# S32K142W_M4 register map
Vendor: NXP Semiconductors; File version: 1.0
CPU: CM4 r0p1, little endian, MPU, FPU, VTOR, 4 interrupt priority bits
Registers are 32-bit, read-write, reset 0x0 unless marked. A register's access mark holds for its fields unless they carry their own. Offsets are from the block's base; [hi:lo] are bit positions; {n}, {i} and the like mark numbered series; 'fields as' and 'values as' point back to an identical list.

## MCM — Core Platform Miscellaneous Control Module
Base 0xE0080000; register names take the prefix MCM_
0x08 PLASC 16-bit ro reset 0x7 — Crossbar Switch (AXBS) Slave Configuration
  [7:0] ASC — Each bit in the ASC field indicates whether there is a corresponding connection to the crossbar switch's slave input port.
    0=A bus slave connection to AXBS input port n is absent; 1=A bus slave connection to AXBS input port n is present
0x0A PLAMC 16-bit ro reset 0x7 — Crossbar Switch (AXBS) Master Configuration
  [7:0] AMC — Each bit in the AMC field indicates whether there is a corresponding connection to the AXBS master input port.
    0=A bus master connection to AXBS input port n is absent; 1=A bus master connection to AXBS input port n is present
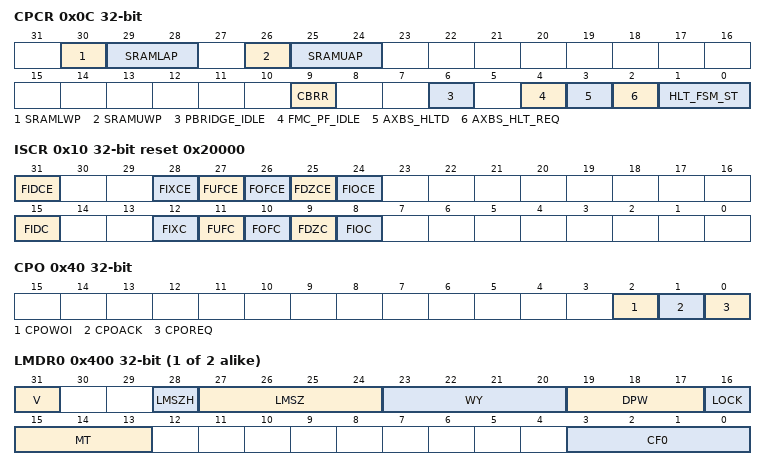
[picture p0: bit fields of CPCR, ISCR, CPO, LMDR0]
0x0C CPCR (reset mask 0xFFFFFFAF) — Core Platform Control Register
  [30] SRAMLWP — SRAM_L Write Protect
  [29:28] SRAMLAP — SRAM_L Arbitration Priority
    0=Round robin; 1=Special round robin (favors SRAM backdoor accesses over the processor); 2=Fixed priority. Processor has highest, backdoor has lowest; 3=Fixed priority. Backdoor has highest, processor has lowest
  [26] SRAMUWP — SRAM_U Write Protect
  [25:24] SRAMUAP — SRAM_U Arbitration Priority
    values as SRAMLAP
  [9] CBRR — Crossbar Round-robin Arbitration Enable
    0=Fixed-priority arbitration; 1=Round-robin arbitration
  [6] PBRIDGE_IDLE ro — Peripheral Bridge Idle
    0=PBRIDGE is not idle; 1=PBRIDGE is currently idle
  [4] FMC_PF_IDLE ro — Flash Memory Controller Program Flash Idle
    0=FMC program flash is not idle; 1=FMC program flash is currently idle
  [3] AXBS_HLTD ro — AXBS Halted
    0=AXBS is not currently halted; 1=AXBS is currently halted
  [2] AXBS_HLT_REQ ro — AXBS Halt Request
    0=AXBS is not receiving halt request; 1=AXBS is receiving halt request
  [1:0] HLT_FSM_ST ro — AXBS Halt State Machine Status
    0=Waiting for request; 1=Waiting for platform idle; 2=Unused state; 3=Platform stalled
0x10 ISCR reset 0x20000 — Interrupt Status and Control Register
  [31] FIDCE — FPU Input Denormal Interrupt Enable
    0=Disable interrupt; 1=Enable interrupt
  [28] FIXCE — FPU Inexact Interrupt Enable
    0=Disable interrupt; 1=Enable interrupt
  [27] FUFCE — FPU Underflow Interrupt Enable
    0=Disable interrupt; 1=Enable interrupt
  [26] FOFCE — FPU Overflow Interrupt Enable
    0=Disable interrupt; 1=Enable interrupt
  [25] FDZCE — FPU Divide-by-Zero Interrupt Enable
    0=Disable interrupt; 1=Enable interrupt
  [24] FIOCE — FPU Invalid Operation Interrupt Enable
    0=Disable interrupt; 1=Enable interrupt
  [15] FIDC ro — FPU Input Denormal Interrupt Status
    0=No interrupt; 1=Interrupt occurred
  [12] FIXC ro — FPU Inexact Interrupt Status
    0=No interrupt; 1=Interrupt occurred
  [11] FUFC ro — FPU Underflow Interrupt Status
    0=No interrupt; 1=Interrupt occurred
  [10] FOFC ro — FPU Overflow Interrupt Status
    0=No interrupt; 1=Interrupt occurred
  [9] FDZC ro — FPU Divide-by-Zero Interrupt Status
    0=No interrupt; 1=Interrupt occurred
  [8] FIOC ro — FPU Invalid Operation Interrupt Status
    0=No interrupt; 1=Interrupt occurred
0x30 PID — Process ID Register
  [7:0] PID — M0_PID and M1_PID for MPU
0x40 CPO — Compute Operation Control Register
  [2] CPOWOI — Compute Operation Wakeup On Interrupt
    0=No effect; 1=When set, the CPOREQ is cleared on any interrupt or exception vector fetch
  [1] CPOACK ro — Compute Operation Acknowledge
    0=Compute operation entry has not completed or compute operation exit has completed; 1=Compute operation entry has completed or compute operation exit has not completed
  [0] CPOREQ — Compute Operation Request
    0=Request is cleared; 1=Request Compute Operation
{0x400+4i} LMDR{i} (i=0..1) reset not defined — Local Memory Descriptor Register
  [31] V ro — Local Memory Valid
    0=LMEMn is not present; 1=LMEMn is present
  [28] LMSZH ro — LMEM Size Hole
    0=LMEMn is a power-of-2 capacity; 1=LMEMn is not a power-of-2, with a capacity is 0.75 * LMSZ
  [27:24] LMSZ ro — LMEM Size
    0=no LMEMn (0 KB); 1=1 KB LMEMn; 2=2 KB LMEMn; 3=4 KB LMEMn; 4=8 KB LMEMn; 5=16 KB LMEMn; 6=32 KB LMEMn; 7=64 KB LMEMn; 8=128 KB LMEMn; 9=256 KB LMEMn; 10=512 KB LMEMn; 11=1024 KB LMEMn; 12=2048 KB LMEMn; 13=4096 KB LMEMn; 14=8192 KB LMEMn; 15=16384 KB LMEMn
  [23:20] WY ro — Level 1 Cache Ways
    0=No Cache; 2=2-Way Set Associative; 4=4-Way Set Associative
  [19:17] DPW ro — LMEM Data Path Width. This field defines the width of the local memory.
    2=LMEMn 32-bits wide; 3=LMEMn 64-bits wide
  [16] LOCK
    0=Writes to the LMDRn[7:0] are allowed; 1=Writes to the LMDRn[7:0] are ignored
  [15:13] MT ro — Memory Type
    0=SRAM_L; 1=SRAM_U
  [3:0] CF0 — Control Field 0 LMDR0[CF0] bit field is Reserved and Read-Only 0 for S32K11x variants.
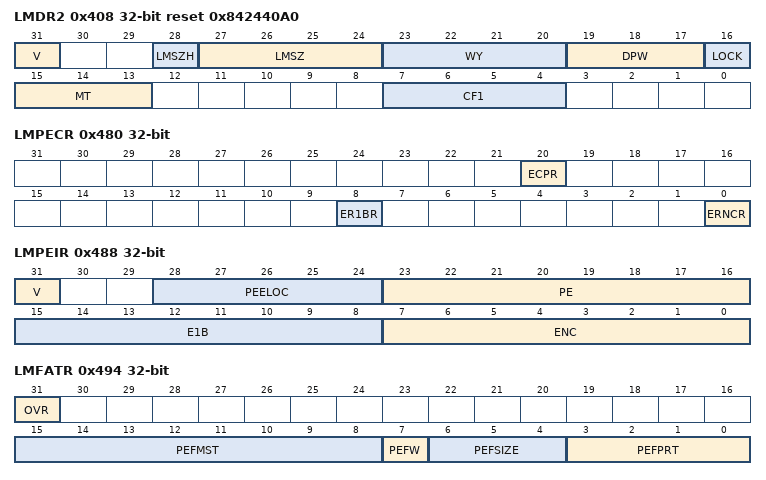
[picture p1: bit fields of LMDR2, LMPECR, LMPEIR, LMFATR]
0x408 LMDR2 reset 0x842440A0 — Local Memory Descriptor Register2
  [31] V ro — Local Memory Valid
    0=LMEMn is not present; 1=LMEMn is present
  [28] LMSZH ro — LMEM Size Hole
    values as LMDR0.LMSZH
  [27:24] LMSZ ro — LMEM Size
    4=4 KB LMEMn
  [23:20] WY ro — Level 1 Cache Ways
    0=No Cache; 2=2-Way Set Associative; 4=4-Way Set Associative
  [19:17] DPW ro — LMEM Data Path Width. This field defines the width of the local memory.
    2=LMEMn 32-bits wide; 3=LMEMn 64-bits wide
  [16] LOCK
    values as LMDR0.LOCK
  [15:13] MT ro — Memory Type
    2=PC Cache
  [7:4] CF1 — Control Field 1
0x480 LMPECR — LMEM Parity and ECC Control Register
  [all] fields
    0=Reporting disabled; 1=Reporting enabled
  [20] ECPR — Enable Cache Parity Reporting
  [8] ER1BR — Enable RAM ECC 1 Bit Reporting This bit field is Reserved and Read-Only 0 for S32K11x variants. This bit field cannot mask ECC reporting, as a result the ECC would always be reported.
  [0] ERNCR — Enable RAM ECC Noncorrectable Reporting This bit field is Reserved and Read-Only 0 for S32K11x variants. This bit field cannot mask ECC reporting, as a result the ECC would always be reported.
0x488 LMPEIR — LMEM Parity and ECC Interrupt Register
  [31] V ro — Valid Bit
  [28:24] PEELOC ro — Parity or ECC Error Location
    0=Non-correctable ECC event from SRAM_L; 1=Non-correctable ECC event from SRAM_U; 8=1-bit correctable ECC event from SRAM_L; 9=1-bit correctable ECC event from SRAM_U; 14=PC tag parity error; 15=PC data parity error
  [23:16] PE write-1-clears — Cache Parity Error
  [15:8] E1B write-1-clears — E1Bn = ECC 1-bit Error n
  [7:0] ENC write-1-clears — ENCn = ECC Noncorrectable Error n
0x490 LMFAR ro — LMEM Fault Address Register
  [31:0] EFADD — ECC Fault Address
0x494 LMFATR ro — LMEM Fault Attribute Register
  [31] OVR — Overrun
  [15:8] PEFMST — Parity/ECC Fault Master Number
  [7] PEFW — Parity/ECC Fault Write
  [6:4] PEFSIZE — Parity/ECC Fault Master Size
    0=8-bit access; 1=16-bit access; 2=32-bit access; 3=64-bit access
  [3:0] PEFPRT — Parity/ECC Fault Protection
0x4A0 LMFDHR ro — LMEM Fault Data High Register
  [31:0] PEFDH — Parity or ECC Fault Data High
0x4A4 LMFDLR ro — LMEM Fault Data Low Register
  [31:0] PEFDL — Parity or ECC Fault Data Low
